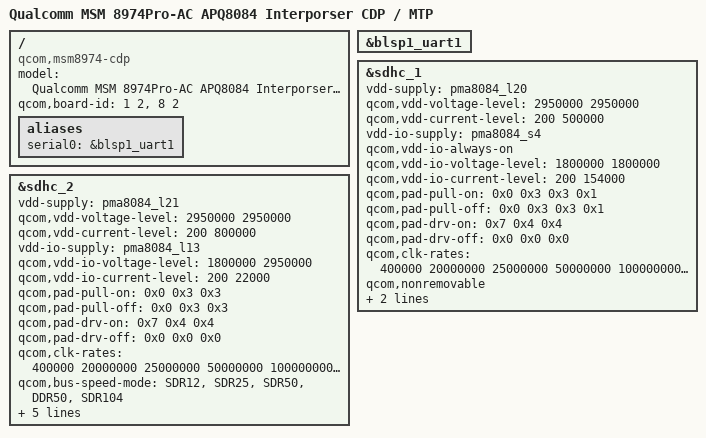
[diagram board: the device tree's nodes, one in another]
/* Copyright (c) 2013, The Linux Foundation. All rights reserved.
 *
 * This program is free software; you can redistribute it and/or modify
 * it under the terms of the GNU General Public License version 2 and
 * only version 2 as published by the Free Software Foundation.
 *
 * This program is distributed in the hope that it will be useful,
 * but WITHOUT ANY WARRANTY; without even the implied warranty of
 * MERCHANTABILITY or FITNESS FOR A PARTICULAR PURPOSE.  See the
 * GNU General Public License for more details.
 */

/dts-v1/;

/include/ "msm8974pro-ac.dtsi"

/ {
	model = "Qualcomm MSM 8974Pro-AC APQ8084 Interporser CDP / MTP";
	compatible = "qcom,msm8974-cdp", "qcom,msm8974", "qcom,cdp";
	qcom,board-id = <1 2>, <8 2>;
};

/ {
	aliases {
		serial0 = &blsp1_uart1;
	};
};

&blsp1_uart1 {
	status = "ok";
};

&sdhc_1 {
	vdd-supply = <&pma8084_l20>;
	qcom,vdd-voltage-level = <2950000 2950000>;
	qcom,vdd-current-level = <200 500000>;

	vdd-io-supply = <&pma8084_s4>;
	qcom,vdd-io-always-on;
	qcom,vdd-io-voltage-level = <1800000 1800000>;
	qcom,vdd-io-current-level = <200 154000>;

	qcom,pad-pull-on = <0x0 0x3 0x3 0x1>; /* no-pull, pull-up, pull-up, pull-down */
	qcom,pad-pull-off = <0x0 0x3 0x3 0x1>; /* no-pull, pull-up, pull-up, pull-down */
	qcom,pad-drv-on = <0x7 0x4 0x4>; /* 16mA, 10mA, 10mA */
	qcom,pad-drv-off = <0x0 0x0 0x0>; /* 2mA, 2mA, 2mA */

	qcom,clk-rates = <400000 20000000 25000000 50000000 100000000 200000000 400000000>;
	qcom,nonremovable;
	qcom,bus-speed-mode = "HS400_1p8v", "HS200_1p8v", "DDR_1p8v";

	status = "ok";
};

&sdhc_2 {
	vdd-supply = <&pma8084_l21>;
	qcom,vdd-voltage-level = <2950000 2950000>;
	qcom,vdd-current-level = <200 800000>;

	vdd-io-supply = <&pma8084_l13>;
	qcom,vdd-io-voltage-level = <1800000 2950000>;
	qcom,vdd-io-current-level = <200 22000>;

	qcom,pad-pull-on = <0x0 0x3 0x3>; /* no-pull, pull-up, pull-up */
	qcom,pad-pull-off = <0x0 0x3 0x3>; /* no-pull, pull-up, pull-up */
	qcom,pad-drv-on = <0x7 0x4 0x4>; /* 16mA, 10mA, 10mA */
	qcom,pad-drv-off = <0x0 0x0 0x0>; /* 2mA, 2mA, 2mA */

	qcom,clk-rates = <400000 20000000 25000000 50000000 100000000 200000000>;
	qcom,bus-speed-mode = "SDR12", "SDR25", "SDR50", "DDR50", "SDR104";

	#address-cells = <0>;
	interrupt-parent = <&sdhc_2>;
	interrupts = <0 1 2>;
	#interrupt-cells = <1>;
	interrupt-map-mask = <0xffffffff>;
	interrupt-map = <0 &intc 0 125 0
			1 &intc 0 221 0
			2 &msmgpio 62 0x3>;
	interrupt-names = "hc_irq", "pwr_irq", "status_irq";

	status = "ok";
};
